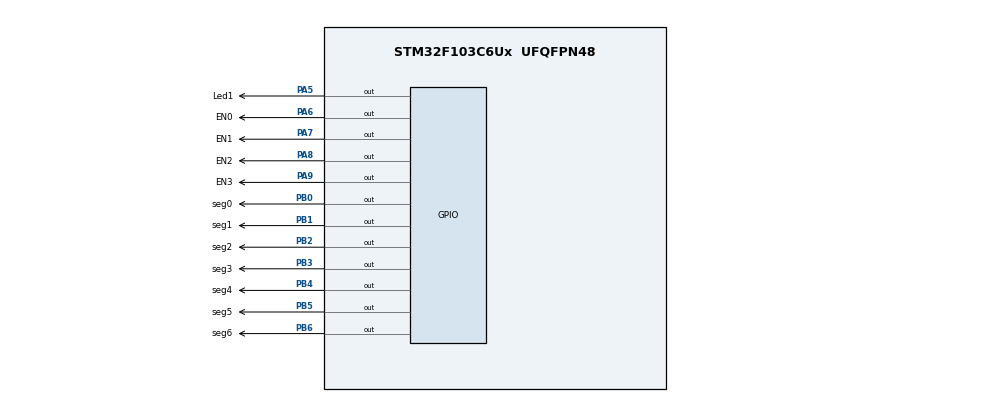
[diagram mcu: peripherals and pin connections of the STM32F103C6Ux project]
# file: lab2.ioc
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Mcu.Family=STM32F1
Mcu.Name=STM32F103C6Ux
Mcu.Package=UFQFPN48
NVIC.PriorityGroup=NVIC_PRIORITYGROUP_4
NVIC.TIM2_IRQn=true\:0\:0\:false\:false\:true\:true\:true\:true
PA13.Mode=Serial_Wire
PA13.Signal=SYS_JTMS-SWDIO
PA14.Mode=Serial_Wire
PA14.Signal=SYS_JTCK-SWCLK
PA5.GPIO_Label=Led1
PA5.Signal=GPIO_Output
PA6.GPIO_Label=EN0
PA6.Signal=GPIO_Output
PA7.GPIO_Label=EN1
PA7.Signal=GPIO_Output
PA8.GPIO_Label=EN2
PA8.Signal=GPIO_Output
PA9.GPIO_Label=EN3
PA9.Signal=GPIO_Output
PB0.GPIO_Label=seg0
PB0.Signal=GPIO_Output
PB1.GPIO_Label=seg1
PB1.Signal=GPIO_Output
PB2.GPIO_Label=seg2
PB2.Signal=GPIO_Output
PB3.GPIO_Label=seg3
PB3.Signal=GPIO_Output
PB4.GPIO_Label=seg4
PB4.Signal=GPIO_Output
PB5.GPIO_Label=seg5
PB5.Signal=GPIO_Output
PB6.GPIO_Label=seg6
PB6.Signal=GPIO_Output
ProjectManager.HeapSize=0x200
ProjectManager.StackSize=0x400
ProjectManager.TargetToolchain=STM32CubeIDE
RCC.APB1Freq_Value=8000000
RCC.APB2Freq_Value=8000000
TIM2.Period=9
TIM2.Prescaler=7999
VP_TIM2_VS_ClockSourceINT.Mode=Internal
board=custom

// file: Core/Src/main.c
/* USER CODE BEGIN Header */
/**
  ******************************************************************************
  * @file           : main.c
  * @brief          : Main program body
  ******************************************************************************
  * @attention
  *
  * Copyright (c) 2023 STMicroelectronics.
  * All rights reserved.
  *
  * This software is licensed under terms that can be found in the LICENSE file
  * in the root directory of this software component.
  * If no LICENSE file comes with this software, it is provided AS-IS.
  *
  ******************************************************************************
  */
/* USER CODE END Header */
#include "main.h"
#include "software_timer.h"

TIM_HandleTypeDef htim2;

void SystemClock_Config(void);
static void MX_GPIO_Init(void);
static void MX_TIM2_Init(void);
/* USER CODE BEGIN PFP */
uint16_t segmentPins[7] = {seg0_Pin, seg1_Pin, seg2_Pin, seg3_Pin, seg4_Pin, seg5_Pin, seg6_Pin};
  GPIO_TypeDef* segmentPorts[7] = {seg0_GPIO_Port, seg1_GPIO_Port, seg2_GPIO_Port, seg3_GPIO_Port, seg4_GPIO_Port, seg5_GPIO_Port, seg6_GPIO_Port};

/* USER CODE END PFP */

/* USER CODE BEGIN 0 */
  void display7SEG(int num) {

    	for (int i = 0; i < 7; i++) {
    	        HAL_GPIO_WritePin(segmentPorts[i], segmentPins[i], GPIO_PIN_SET);
    	    }
    	if (num == 0) {
    		for (int i = 0; i < 6; i++) {
    			HAL_GPIO_WritePin(segmentPorts[i], segmentPins[i], GPIO_PIN_RESET);
    		}
    	} else if (num == 1) {
    		HAL_GPIO_WritePin(segmentPorts[1], segmentPins[1], GPIO_PIN_RESET);
    		HAL_GPIO_WritePin(segmentPorts[2], segmentPins[2], GPIO_PIN_RESET);
    	} else if (num == 2) {
    		for (int i = 0; i < 7; i++) {
    			if (i == 2 || i == 5) continue;
    			HAL_GPIO_WritePin(segmentPorts[i], segmentPins[i], GPIO_PIN_RESET);
    		}
    	} else if (num == 3) {
    		for (int i = 0; i < 7; i++) {
    			if (i == 4 || i == 5) continue;
    			HAL_GPIO_WritePin(segmentPorts[i], segmentPins[i], GPIO_PIN_RESET);
    		}
    	} else if (num == 4) {
    		for (int i = 0; i < 7; i++) {
    			if (i == 0 || i == 3 || i == 4) continue;
    			HAL_GPIO_WritePin(segmentPorts[i], segmentPins[i], GPIO_PIN_RESET);
    		}
    	} else if (num == 5) {
    		for (int i = 0; i < 7; i++) {
    			if (i == 1 || i == 4) continue;
    			HAL_GPIO_WritePin(segmentPorts[i], segmentPins[i], GPIO_PIN_RESET);
    		}
    	} else if (num == 6) {
    		for (int i = 0; i < 7; i++) {
    			if (i == 1) continue;
    			HAL_GPIO_WritePin(segmentPorts[i], segmentPins[i], GPIO_PIN_RESET);
    		}
    	} else if (num == 7) {
    		for (int i = 0; i < 3; i++) {
    			HAL_GPIO_WritePin(segmentPorts[i], segmentPins[i], GPIO_PIN_RESET);
    		}
    	} else if (num == 8) {
    		for (int i = 0; i < 7; i++) {
    			HAL_GPIO_WritePin(segmentPorts[i], segmentPins[i], GPIO_PIN_RESET);
    		}
    	} else if (num == 9) {
    		for (int i = 0; i < 7; i++) {
    			if (i == 4) continue;
    			HAL_GPIO_WritePin(segmentPorts[i], segmentPins[i], GPIO_PIN_RESET);
    		}
    	}

    }
const int MAX_LED = 4;
int currentNumber = 1;
int index_led = 0;
int led_buffer[4] = {0, 2, 5, 7};
void update7SEG(int index){
    switch (index){
        case 0:
            //Display the first 7SEG with led_buffer[0]
        	HAL_GPIO_WritePin(EN0_GPIO_Port, EN0_Pin, GPIO_PIN_RESET);
			HAL_GPIO_WritePin(EN1_GPIO_Port, EN1_Pin, GPIO_PIN_SET);
			HAL_GPIO_WritePin(EN2_GPIO_Port, EN2_Pin, GPIO_PIN_SET);
			HAL_GPIO_WritePin(EN3_GPIO_Port, EN3_Pin, GPIO_PIN_SET);
			currentNumber = led_buffer[0];
			break;
		case 1:
			//Display the second 7SEG with led_buffer[1]
			HAL_GPIO_WritePin(EN0_GPIO_Port, EN0_Pin, GPIO_PIN_SET);
			HAL_GPIO_WritePin(EN1_GPIO_Port, EN1_Pin, GPIO_PIN_RESET);
			HAL_GPIO_WritePin(EN2_GPIO_Port, EN2_Pin, GPIO_PIN_SET);
			HAL_GPIO_WritePin(EN3_GPIO_Port, EN3_Pin, GPIO_PIN_SET);
			currentNumber = led_buffer[1];
			break;
		case 2:
			//Display the third 7SEG with led_buffer[2]
			HAL_GPIO_WritePin(EN0_GPIO_Port, EN0_Pin, GPIO_PIN_SET);
			HAL_GPIO_WritePin(EN1_GPIO_Port, EN1_Pin, GPIO_PIN_SET);
			HAL_GPIO_WritePin(EN2_GPIO_Port, EN2_Pin, GPIO_PIN_RESET);
			HAL_GPIO_WritePin(EN3_GPIO_Port, EN3_Pin, GPIO_PIN_SET);
			currentNumber = led_buffer[2];
			break;
		case 3:
			//Display the forth 7SEG with led_buffer[3]
			HAL_GPIO_WritePin(EN0_GPIO_Port, EN0_Pin, GPIO_PIN_SET);
			HAL_GPIO_WritePin(EN1_GPIO_Port, EN1_Pin, GPIO_PIN_SET);
			HAL_GPIO_WritePin(EN2_GPIO_Port, EN2_Pin, GPIO_PIN_SET);
			HAL_GPIO_WritePin(EN3_GPIO_Port, EN3_Pin, GPIO_PIN_RESET);
			currentNumber = led_buffer[3];
			break;
        default:
            break;
    }
    display7SEG(currentNumber);
}
void updateClockBuffer(int hour, int minute) {
    led_buffer[0] = hour /10;
    led_buffer[1] = hour% 10;
    led_buffer[2] = minute/10;
    led_buffer[3] = minute % 10;
}
/* USER CODE END 0 */

int main(void)
{

  /* MCU Configuration--------------------------------------------------------*/

  /* Reset of all peripherals, Initializes the Flash interface and the Systick. */
  HAL_Init();

  /* Configure the system clock */
  SystemClock_Config();

  /* Initialize all configured peripherals */
  MX_GPIO_Init();
  MX_TIM2_Init();
  /* USER CODE BEGIN 2 */
  HAL_TIM_Base_Start_IT (& htim2 ) ;
  /* USER CODE END 2 */

  /* Infinite loop */
  /* USER CODE BEGIN WHILE */
setTimer1(100);
int hour = 15, minute = 8, second = 50;
while (1)
   {
      /* USER CODE END WHILE */
  	  if (timer1_flag == 1) {
  		  index_led++;
		  if (index_led >= MAX_LED) {
			  index_led = 0;
		  }
		  update7SEG(index_led);
		  HAL_GPIO_TogglePin(DOT_GPIO_Port, DOT_Pin);
		  setTimer1(100);
		  second++;
		  if (second >= 60){
			  second = 0;
			  minute++;
		  }
		  if(minute >= 60){
			  minute = 0;
			  hour++;
		  }
		  if(hour >=24){
			  hour = 0;
		  }
		  updateClockBuffer(hour,minute);
  	 }
   }
}

void SystemClock_Config(void)
{
  RCC_OscInitTypeDef RCC_OscInitStruct = {0};
  RCC_ClkInitTypeDef RCC_ClkInitStruct = {0};

  /** Initializes the RCC Oscillators according to the specified parameters
  * in the RCC_OscInitTypeDef structure.
  */
  RCC_OscInitStruct.OscillatorType = RCC_OSCILLATORTYPE_HSI;
  RCC_OscInitStruct.HSIState = RCC_HSI_ON;
  RCC_OscInitStruct.HSICalibrationValue = RCC_HSICALIBRATION_DEFAULT;
  RCC_OscInitStruct.PLL.PLLState = RCC_PLL_NONE;
  if (HAL_RCC_OscConfig(&RCC_OscInitStruct) != HAL_OK)
  {
    Error_Handler();
  }

  /** Initializes the CPU, AHB and APB buses clocks
  */
  RCC_ClkInitStruct.ClockType = RCC_CLOCKTYPE_HCLK|RCC_CLOCKTYPE_SYSCLK
                              |RCC_CLOCKTYPE_PCLK1|RCC_CLOCKTYPE_PCLK2;
  RCC_ClkInitStruct.SYSCLKSource = RCC_SYSCLKSOURCE_HSI;
  RCC_ClkInitStruct.AHBCLKDivider = RCC_SYSCLK_DIV1;
  RCC_ClkInitStruct.APB1CLKDivider = RCC_HCLK_DIV1;
  RCC_ClkInitStruct.APB2CLKDivider = RCC_HCLK_DIV1;

  if (HAL_RCC_ClockConfig(&RCC_ClkInitStruct, FLASH_LATENCY_0) != HAL_OK)
  {
    Error_Handler();
  }
}

static void MX_TIM2_Init(void)
{

  TIM_ClockConfigTypeDef sClockSourceConfig = {0};
  TIM_MasterConfigTypeDef sMasterConfig = {0};

  htim2.Instance = TIM2;
  htim2.Init.Prescaler = 7999;
  htim2.Init.CounterMode = TIM_COUNTERMODE_UP;
  htim2.Init.Period = 9;
  htim2.Init.ClockDivision = TIM_CLOCKDIVISION_DIV1;
  htim2.Init.AutoReloadPreload = TIM_AUTORELOAD_PRELOAD_DISABLE;
  if (HAL_TIM_Base_Init(&htim2) != HAL_OK)
  {
    Error_Handler();
  }
  sClockSourceConfig.ClockSource = TIM_CLOCKSOURCE_INTERNAL;
  if (HAL_TIM_ConfigClockSource(&htim2, &sClockSourceConfig) != HAL_OK)
  {
    Error_Handler();
  }
  sMasterConfig.MasterOutputTrigger = TIM_TRGO_RESET;
  sMasterConfig.MasterSlaveMode = TIM_MASTERSLAVEMODE_DISABLE;
  if (HAL_TIMEx_MasterConfigSynchronization(&htim2, &sMasterConfig) != HAL_OK)
  {
    Error_Handler();
  }

}

static void MX_GPIO_Init(void)
{
  GPIO_InitTypeDef GPIO_InitStruct = {0};

  /* GPIO Ports Clock Enable */
  __HAL_RCC_GPIOA_CLK_ENABLE();
  __HAL_RCC_GPIOB_CLK_ENABLE();

  /*Configure GPIO pin Output Level */
  HAL_GPIO_WritePin(GPIOA, DOT_Pin|Led1_Pin|EN0_Pin|EN1_Pin
                          |EN2_Pin|EN3_Pin, GPIO_PIN_RESET);

  /*Configure GPIO pin Output Level */
  HAL_GPIO_WritePin(GPIOB, seg0_Pin|seg1_Pin|seg2_Pin|seg3_Pin
                          |seg4_Pin|seg5_Pin|seg6_Pin, GPIO_PIN_RESET);

  /*Configure GPIO pins : DOT_Pin Led1_Pin EN0_Pin EN1_Pin
                           EN2_Pin EN3_Pin */
  GPIO_InitStruct.Pin = DOT_Pin|Led1_Pin|EN0_Pin|EN1_Pin
                          |EN2_Pin|EN3_Pin;
  GPIO_InitStruct.Mode = GPIO_MODE_OUTPUT_PP;
  GPIO_InitStruct.Pull = GPIO_NOPULL;
  GPIO_InitStruct.Speed = GPIO_SPEED_FREQ_LOW;
  HAL_GPIO_Init(GPIOA, &GPIO_InitStruct);

  /*Configure GPIO pins : seg0_Pin seg1_Pin seg2_Pin seg3_Pin
                           seg4_Pin seg5_Pin seg6_Pin */
  GPIO_InitStruct.Pin = seg0_Pin|seg1_Pin|seg2_Pin|seg3_Pin
                          |seg4_Pin|seg5_Pin|seg6_Pin;
  GPIO_InitStruct.Mode = GPIO_MODE_OUTPUT_PP;
  GPIO_InitStruct.Pull = GPIO_NOPULL;
  GPIO_InitStruct.Speed = GPIO_SPEED_FREQ_LOW;
  HAL_GPIO_Init(GPIOB, &GPIO_InitStruct);

}

/* USER CODE BEGIN 4 */

int counter = 10;
void HAL_TIM_PeriodElapsedCallback ( TIM_HandleTypeDef * htim ) {
	timerRun();

}
/* USER CODE END 4 */

void Error_Handler(void)
{
  __disable_irq();
  while (1)
  {
  }
}
